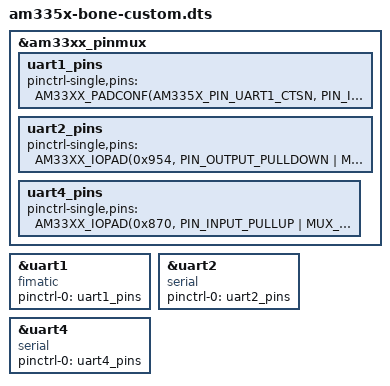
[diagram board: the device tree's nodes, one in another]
/* This line includes the existing Beaglebone Black
Device Tree Source file so portions can be overridden */

#include "am335x-boneblack.dts"

&am33xx_pinmux {

	uart1_pins: uart1_pins {
		pinctrl-single,pins = <
			AM33XX_PADCONF(AM335X_PIN_UART1_CTSN, PIN_INPUT, MUX_MODE0)
			AM33XX_PADCONF(AM335X_PIN_UART1_RTSN, PIN_OUTPUT_PULLDOWN, MUX_MODE0)
			AM33XX_PADCONF(AM335X_PIN_UART1_RXD, PIN_INPUT_PULLUP, MUX_MODE0)
			AM33XX_PADCONF(AM335X_PIN_UART1_TXD, PIN_OUTPUT_PULLDOWN, MUX_MODE0)
		>;
	};

	uart2_pins: uart2_pins {
        pinctrl-single,pins = < 
			AM33XX_IOPAD(0x954, PIN_OUTPUT_PULLDOWN | MUX_MODE1)
			AM33XX_IOPAD(0x950, PIN_INPUT_PULLUP | MUX_MODE1)
			>;
	};
	
	uart4_pins: uart4_pins {
	pinctrl-single,pins = <
		AM33XX_IOPAD(0x870, PIN_INPUT_PULLUP | MUX_MODE6)
		AM33XX_IOPAD(0x874, PIN_OUTPUT_PULLDOWN | MUX_MODE6)
		>;
	};

};


&uart1 {
	compatible = "fimatic";					// Добавлена совместимость с модулем драйвера Fimatic_Drv_Main.ko
	status = "okay";
	pinctrl-names = "default";
	pinctrl-0 = <&uart1_pins>;

};

&uart2 {
	compatible = "serial";
	status = "okay";
	pinctrl-names = "default";
	pinctrl-0 = <&uart2_pins>;
};

&uart4 {
	compatible = "serial";
	status = "okay";
	pinctrl-names = "default";
	pinctrl-0 = <&uart4_pins>;
};
